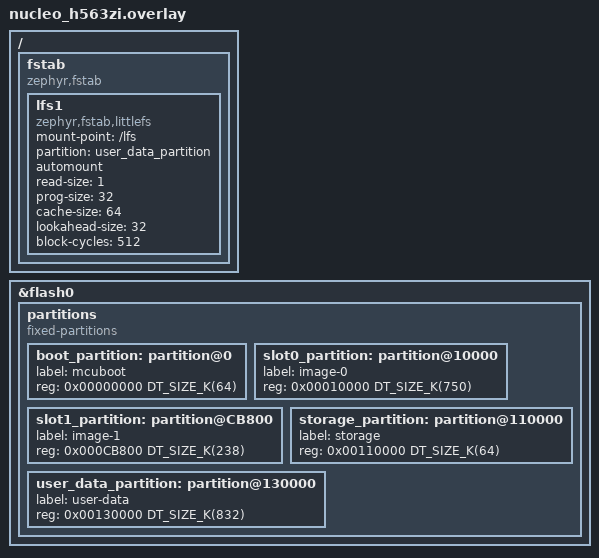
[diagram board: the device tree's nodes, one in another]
// /delete-node/ &sram1;
// /delete-node/ &sram2;
// /delete-node/ &sram3;

/ {

	// sram1: memory@20000000 {
	// 	compatible = "zephyr,memory-region", "mmio-sram";
	// 	reg = <0x20000000 DT_SIZE_K(640)>;
	// 	zephyr,memory-region = "SRAM1";
	// };


    fstab {
		compatible = "zephyr,fstab";
		lfs1: lfs1 {
			compatible = "zephyr,fstab,littlefs";
			mount-point = "/lfs";
			partition = <&user_data_partition>;
			automount;
			read-size = <1>;
			prog-size = <32>;
			cache-size = <64>;
			lookahead-size = <32>;
			block-cycles = <512>;
		};
	};
};


/delete-node/ &slot0_partition;
/delete-node/ &slot1_partition;
/delete-node/ &storage_partition;

&flash0 {
	partitions {
		compatible = "fixed-partitions";
		#address-cells = <1>;
		#size-cells = <1>;

		boot_partition: partition@0 {
			label = "mcuboot";
			reg = <0x00000000 DT_SIZE_K(64)>;
		};
		slot0_partition: partition@10000 {
			label = "image-0";
			reg = <0x00010000 DT_SIZE_K(750)>;
		};
		slot1_partition: partition@CB800 {
			label = "image-1";
			reg = <0x000CB800 DT_SIZE_K(238)>;
		};
		storage_partition: partition@110000 {
			label = "storage";
			reg = <0x00110000 DT_SIZE_K(64)>;
		};
        user_data_partition: partition@130000 {
            label = "user-data";
            reg = <0x00130000 DT_SIZE_K(832)>;
        };


	};
};

